# STM32G563xx register map
File version: 1.0
Registers are 32-bit, read-write, reset 0x0 unless marked. A register's access mark holds for its fields unless they carry their own. Offsets are from the block's base; [hi:lo] are bit positions; {n}, {i} and the like mark numbered series.

## CRS — Clock Recovery System (CRS)
Base 0x40006000
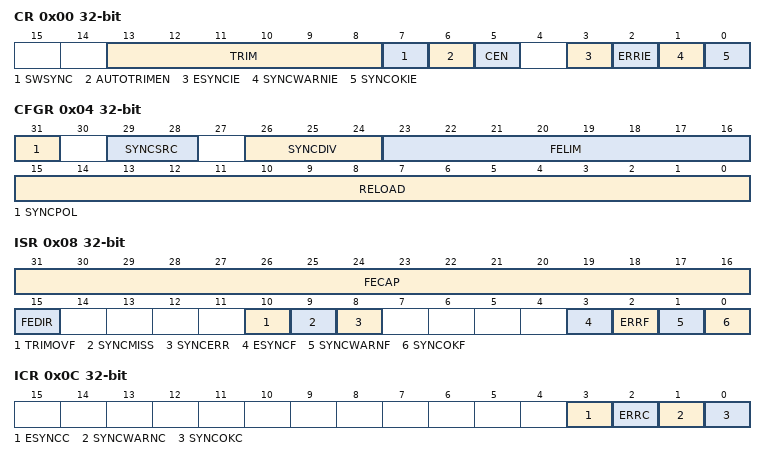
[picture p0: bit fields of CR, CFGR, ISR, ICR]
0x00 CR — CRS control register
  [13:8] TRIM
  [7] SWSYNC — Generate software SYNC event
  [6] AUTOTRIMEN — Automatic trimming enable
  [5] CEN
  [3] ESYNCIE
  [2] ERRIE
  [1] SYNCWARNIE
  [0] SYNCOKIE
0x04 CFGR — CRS configuration register
  [31] SYNCPOL — SYNC polarity selection
  [29:28] SYNCSRC — SYNC signal source selection
  [26:24] SYNCDIV — SYNC divider
  [23:16] FELIM — Frequency error limit
  [15:0] RELOAD — Counter reload value
0x08 ISR ro — CRS interrupt and status register
  [31:16] FECAP — Frequency error capture
  [15] FEDIR — Frequency error direction
  [10] TRIMOVF
  [9] SYNCMISS — SYNC missed
  [8] SYNCERR — SYNC error
  [3] ESYNCF — Expected SYNC flag
  [2] ERRF — Error flag
  [1] SYNCWARNF — SYNC warning flag
  [0] SYNCOKF — SYNC event OK flag
0x0C ICR — CRS interrupt flag clear register
  [3] ESYNCC — Expected SYNC clear flag
  [2] ERRC — Error clear flag
  [1] SYNCWARNC — SYNC warning clear flag
  [0] SYNCOKC — SYNC event OK clear flag

## DTS — Digital temperature sensor (DTS)
Base 0x40008C00
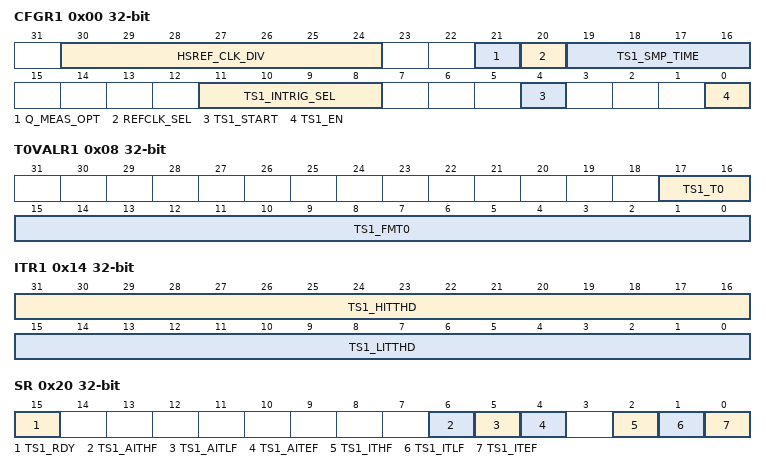
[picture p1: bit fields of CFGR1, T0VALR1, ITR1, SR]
0x00 CFGR1 — Temperature sensor configuration register 1
  [30:24] HSREF_CLK_DIV, [21] Q_MEAS_OPT, [20] REFCLK_SEL, [19:16] TS1_SMP_TIME, [11:8] TS1_INTRIG_SEL, [4] TS1_START, [0] TS1_EN
0x08 T0VALR1 ro — Temperature sensor T0 value register 1
  [17:16] TS1_T0, [15:0] TS1_FMT0
0x10 RAMPVALR ro — Temperature sensor ramp value register
  [15:0] TS1_RAMP_COEFF
0x14 ITR1 — Temperature sensor interrupt threshold register 1
  [31:16] TS1_HITTHD, [15:0] TS1_LITTHD
0x1C DR — Temperature sensor data register
  [15:0] TS1_MFREQ
0x20 SR ro — Temperature sensor status register
  [15] TS1_RDY, [6] TS1_AITHF, [5] TS1_AITLF, [4] TS1_AITEF, [2] TS1_ITHF, [1] TS1_ITLF, [0] TS1_ITEF
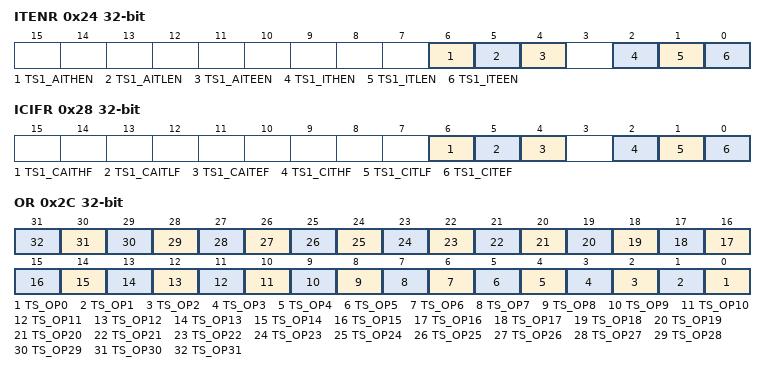
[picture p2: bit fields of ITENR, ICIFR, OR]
0x24 ITENR — Temperature sensor interrupt enable register
  [6] TS1_AITHEN, [5] TS1_AITLEN, [4] TS1_AITEEN, [2] TS1_ITHEN, [1] TS1_ITLEN, [0] TS1_ITEEN
0x28 ICIFR — Temperature sensor clear interrupt flag register
  [6] TS1_CAITHF, [5] TS1_CAITLF, [4] TS1_CAITEF, [2] TS1_CITHF, [1] TS1_CITLF, [0] TS1_CITEF
0x2C OR — Temperature sensor option register
  [n] TS_OP{n} (n=0..31) — general purpose option bits

## FDCAN_CONFIG — FD Controller Area Network Configuration
Base 0x4000A100
0x00 CKDIV — FDCAN CFG clock divider register
  [3:0] PDIV — input clock divider

## UCPD1 — USB Power Delivery Interface (UCPD)
Base 0x4000DC00
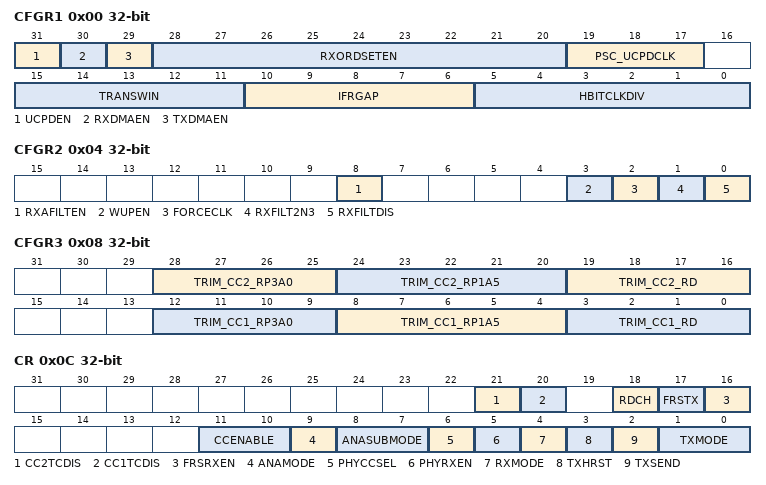
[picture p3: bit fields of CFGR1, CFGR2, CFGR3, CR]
0x00 CFGR1 — UCPD configuration register 1
  [31] UCPDEN — UCPD peripheral enable
  [30] RXDMAEN
  [29] TXDMAEN
  [28:20] RXORDSETEN
  [19:17] PSC_UCPDCLK
  [15:11] TRANSWIN
  [10:6] IFRGAP
  [5:0] HBITCLKDIV
0x04 CFGR2 — UCPD configuration register 2
  [8] RXAFILTEN — Rx analog filter enable
  [3] WUPEN
  [2] FORCECLK
  [1] RXFILT2N3
  [0] RXFILTDIS
0x08 CFGR3 — UCPD configuration register 3
  [28:25] TRIM_CC2_RP3A0 — Rp3.0A trim value on CC2
  [24:20] TRIM_CC2_RP1A5 — Rp1.5A trim value on CC2
  [19:16] TRIM_CC2_RD — Rd trim value on CC2
  [12:9] TRIM_CC1_RP3A0 — Rp3.0A trim value on CC1
  [8:4] TRIM_CC1_RP1A5 — Rp1.5A trim value on CC1
  [3:0] TRIM_CC1_RD — Rd trim value on CC1
0x0C CR — UCPD control register
  [21] CC2TCDIS
  [20] CC1TCDIS
  [18] RDCH — Rdch condition drive
  [17] FRSTX
  [16] FRSRXEN
  [11:10] CCENABLE — CC line enable
  [9] ANAMODE
  [8:7] ANASUBMODE — Analog PHY sub-mode
  [6] PHYCCSEL
  [5] PHYRXEN
  [4] RXMODE — Receiver mode
  [3] TXHRST
  [2] TXSEND
  [1:0] TXMODE — Type of Tx packet
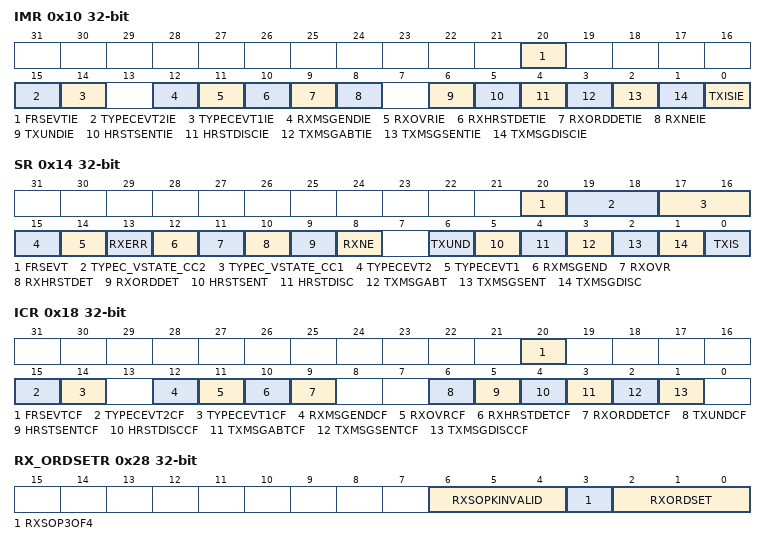
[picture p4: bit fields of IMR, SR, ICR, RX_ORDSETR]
0x10 IMR — UCPD interrupt mask register
  [20] FRSEVTIE — FRSEVT interrupt enable
  [15] TYPECEVT2IE
  [14] TYPECEVT1IE
  [12] RXMSGENDIE
  [11] RXOVRIE — RXOVR interrupt enable
  [10] RXHRSTDETIE
  [9] RXORDDETIE
  [8] RXNEIE — RXNE interrupt enable
  [6] TXUNDIE — TXUND interrupt enable
  [5] HRSTSENTIE
  [4] HRSTDISCIE
  [3] TXMSGABTIE
  [2] TXMSGSENTIE
  [1] TXMSGDISCIE
  [0] TXISIE — TXIS interrupt enable
0x14 SR ro — UCPD status register
  [20] FRSEVT — FRS detection event
  [19:18] TYPEC_VSTATE_CC2 — CC2 line voltage level
  [17:16] TYPEC_VSTATE_CC1
  [15] TYPECEVT2
  [14] TYPECEVT1
  [13] RXERR — Receive message error
  [12] RXMSGEND — Rx message received
  [11] RXOVR
  [10] RXHRSTDET
  [9] RXORDDET
  [8] RXNE
  [6] TXUND
  [5] HRSTSENT — Hard Reset message sent
  [4] HRSTDISC — Hard Reset discarded
  [3] TXMSGABT — Transmit message abort
  [2] TXMSGSENT
  [1] TXMSGDISC
  [0] TXIS
0x18 ICR — UCPD interrupt clear register
  [20] FRSEVTCF, [15] TYPECEVT2CF, [14] TYPECEVT1CF, [12] RXMSGENDCF, [11] RXOVRCF, [10] RXHRSTDETCF, [9] RXORDDETCF, [6] TXUNDCF, [5] HRSTSENTCF, [4] HRSTDISCCF, [3] TXMSGABTCF, [2] TXMSGSENTCF, [1] TXMSGDISCCF
0x1C TX_ORDSETR — UCPD Tx ordered set type register
  [19:0] TXORDSET — Ordered set to transmit
0x20 TX_PAYSZR — UCPD Tx payload size register
  [9:0] TXPAYSZ
0x24 TXDR — UCPD Tx data register
  [7:0] TXDATA — Data byte to transmit
0x28 RX_ORDSETR ro — UCPD Rx ordered set register
  [6:4] RXSOPKINVALID, [3] RXSOP3OF4, [2:0] RXORDSET
0x2C RX_PAYSZR ro — UCPD Rx payload size register
  [9:0] RXPAYSZ
0x30 RXDR ro — UCPD receive data register
  [7:0] RXDATA — Data byte received
0x34 RX_ORDEXTR1 — UCPD Rx ordered set extension register 1
  [19:0] RXSOPX1 — Ordered set 1 received
0x38 RX_ORDEXTR2 — UCPD Rx ordered set extension register 2
  [19:0] RXSOPX2 — Ordered set 2 received
